# ATSAMG55G19 register map
Vendor: Microchip Technology; Series: SAMG55; File version: 0
CPU: CM4 r0p1, little endian, MPU, FPU, 4 interrupt priority bits, 50 interrupts
Registers are 32-bit, read-write, reset 0x0 unless marked. A register's access mark holds for its fields unless they carry their own. Offsets are from the block's base; [hi:lo] are bit positions.

## MEM2MEM — Memory to Memory
Base 0x40028000
0x00 THR — Memory to Memory Transfer Holding Register
  [31:0] THDATA — Transfer Holding Data
0x04 MR — Memory to Memory Mode Register
  [1:0] TSIZE — Transfer Size
    0=T_8BIT (The buffer size is defined in byte.); 1=T_16BIT (The buffer size is defined in half-word (16-bit).); 2=T_32BIT (The buffer size is defined in word (32-bit). Default value.)
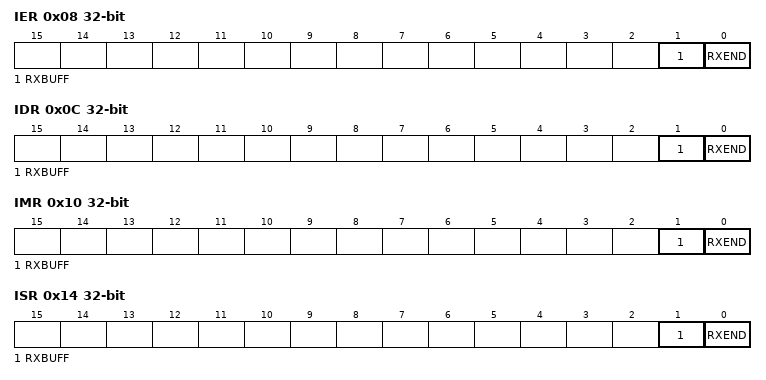
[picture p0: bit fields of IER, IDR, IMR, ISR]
0x08 IER wo — Memory to Memory Interrupt Enable Register
  [1] RXBUFF — Buffer Full Interrupt Enable
  [0] RXEND — End of Transfer Interrupt Enable
0x0C IDR wo — Memory to Memory Interrupt Disable Register
  [1] RXBUFF — Buffer Full Interrupt Disable
  [0] RXEND — End of Transfer Interrupt Disable
0x10 IMR ro — Memory to Memory Interrupt Mask Register
  [1] RXBUFF — Buffer Full Interrupt Mask
  [0] RXEND — End of Transfer Interrupt Mask
0x14 ISR ro — Memory to Memory Interrupt Status Register
  [1] RXBUFF — Buffer Full
  [0] RXEND — End of Transfer
0x100 RPR — Receive Pointer Register
  [31:0] RXPTR
0x104 RCR — Receive Counter Register
  [15:0] RXCTR
0x108 TPR — Transmit Pointer Register
  [31:0] TXPTR — Transmit Counter Register
0x10C TCR — Transmit Counter Register
  [15:0] TXCTR
0x110 RNPR — Receive Next Pointer Register
  [31:0] RXNPTR — Receive Next Pointer
0x114 RNCR — Receive Next Counter Register
  [15:0] RXNCTR — Receive Next Counter
0x118 TNPR — Transmit Next Pointer Register
  [31:0] TXNPTR — Transmit Next Pointer
0x11C TNCR — Transmit Next Counter Register
  [15:0] TXNCTR — Transmit Counter Next
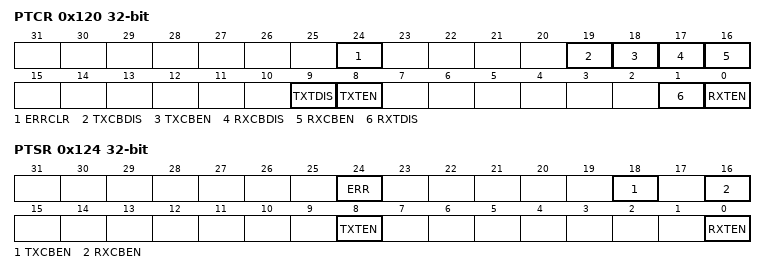
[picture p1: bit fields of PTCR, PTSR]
0x120 PTCR wo — Transfer Control Register
  [24] ERRCLR — Transfer Bus Error Clear
  [19] TXCBDIS — Transmitter Circular Buffer Disable
  [18] TXCBEN — Transmitter Circular Buffer Enable
  [17] RXCBDIS — Receiver Circular Buffer Disable
  [16] RXCBEN — Receiver Circular Buffer Enable
  [9] TXTDIS — Transmitter Transfer Disable
  [8] TXTEN — Transmitter Transfer Enable
  [1] RXTDIS — Receiver Transfer Disable
  [0] RXTEN — Receiver Transfer Enable
0x124 PTSR ro — Transfer Status Register
  [24] ERR — Transfer Bus Error
  [18] TXCBEN — Transmitter Circular Buffer Enable
  [16] RXCBEN — Receiver Circular Buffer Enable
  [8] TXTEN — Transmitter Transfer Enable
  [0] RXTEN — Receiver Transfer Enable

## PDMIC0 — Pulse Density Modulation Interface Controller
Base 0x4002C000; register names take the prefix PDMIC_
Same registers: PDMIC1 0x40030000
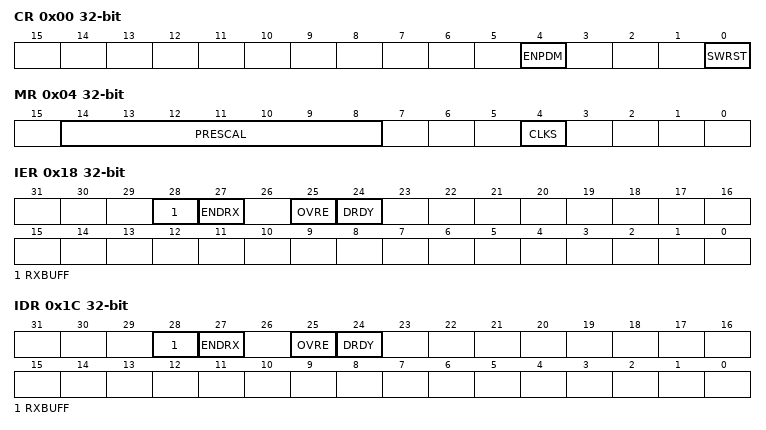
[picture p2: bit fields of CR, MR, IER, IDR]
0x00 CR — Control Register
  [4] ENPDM — Enable PDM
  [0] SWRST — Software Reset
0x04 MR — Mode Register
  [14:8] PRESCAL — Prescaler Rate Selection
  [4] CLKS — Clock Source Selection
0x14 CDR ro — Converted Data Register
  [31:0] DATA — Data Converted
0x18 IER wo — Interrupt Enable Register
  [28] RXBUFF — Receive Buffer Full Interrupt Enable
  [27] ENDRX — End of Receive Buffer Interrupt Enable
  [25] OVRE — Overrun Error Interrupt Enable
  [24] DRDY — Data Ready Interrupt Enable
0x1C IDR wo — Interrupt Disable Register
  [28] RXBUFF — Receive Buffer Full Interrupt Disable
  [27] ENDRX — End of Receive Buffer Interrupt Disable
  [25] OVRE — General Overrun Error Interrupt Disable
  [24] DRDY — Data Ready Interrupt Disable
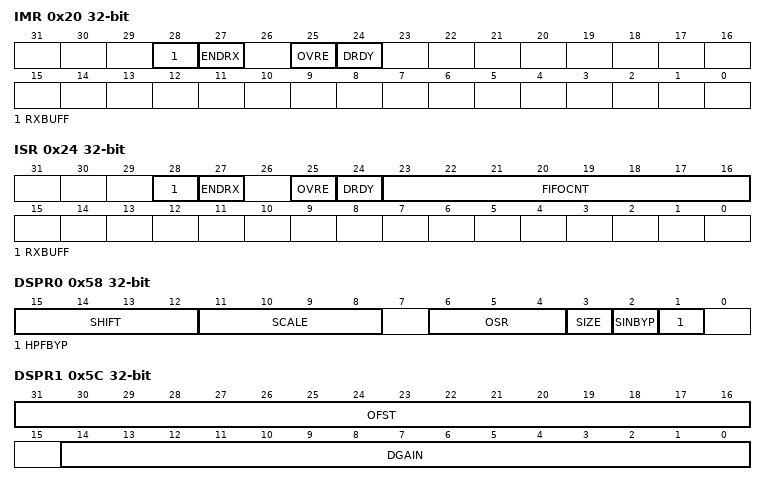
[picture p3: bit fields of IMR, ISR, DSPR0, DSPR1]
0x20 IMR ro — Interrupt Mask Register
  [28] RXBUFF — Receive Buffer Full Interrupt Mask
  [27] ENDRX — End of Receive Buffer Interrupt Mask
  [25] OVRE — General Overrun Error Interrupt Mask
  [24] DRDY — Data Ready Interrupt Mask
0x24 ISR ro — Interrupt Status Register
  [28] RXBUFF — RX Buffer Full
  [27] ENDRX — End of RX Buffer
  [25] OVRE — Overrun Error
  [24] DRDY — Data Ready
  [23:16] FIFOCNT — FIFO Count
0x58 DSPR0 — DSP Configuration Register 0
  [15:12] SHIFT — Data Shift
  [11:8] SCALE — Data Scale
  [6:4] OSR — Oversampling Ratio
    0=Oversampling ratio is 128; 1=Oversampling ratio is 64
  [3] SIZE — Data Size
  [2] SINBYP — SINCC Filter Bypass
  [1] HPFBYP — High-Pass Filter Bypass
0x5C DSPR1 — DSP Configuration Register 1
  [31:16] OFST — Offset Correction
  [14:0] DGAIN — Gain Correction
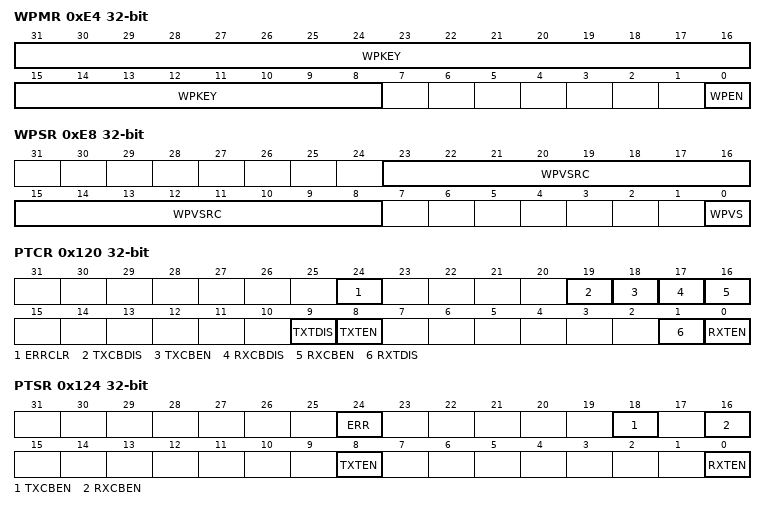
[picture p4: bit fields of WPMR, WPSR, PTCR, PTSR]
0xE4 WPMR — Write Protection Mode Register
  [31:8] WPKEY — Write Protect Key
    0x414443=PASSWD (Writing any other value in this field aborts the write operation of the WPEN bit.Always reads as 0.)
  [0] WPEN — Write Protection Enable
0xE8 WPSR ro — Write Protection Status Register
  [23:8] WPVSRC — Write Protection Violation Source
  [0] WPVS — Write Protection Violation Status
0x100 RPR — Receive Pointer Register
  [31:0] RXPTR
0x104 RCR — Receive Counter Register
  [15:0] RXCTR
0x110 RNPR — Receive Next Pointer Register
  [31:0] RXNPTR — Receive Next Pointer
0x114 RNCR — Receive Next Counter Register
  [15:0] RXNCTR — Receive Next Counter
0x120 PTCR wo — Transfer Control Register
  [24] ERRCLR — Transfer Bus Error Clear
  [19] TXCBDIS — Transmitter Circular Buffer Disable
  [18] TXCBEN — Transmitter Circular Buffer Enable
  [17] RXCBDIS — Receiver Circular Buffer Disable
  [16] RXCBEN — Receiver Circular Buffer Enable
  [9] TXTDIS — Transmitter Transfer Disable
  [8] TXTEN — Transmitter Transfer Enable
  [1] RXTDIS — Receiver Transfer Disable
  [0] RXTEN — Receiver Transfer Enable
0x124 PTSR ro — Transfer Status Register
  [24] ERR — Transfer Bus Error
  [18] TXCBEN — Transmitter Circular Buffer Enable
  [16] RXCBEN — Receiver Circular Buffer Enable
  [8] TXTEN — Transmitter Transfer Enable
  [0] RXTEN — Receiver Transfer Enable

## Notices in the file
Copyright (c) 2026 Microchip Technology Inc.
SPDX-License-Identifier: Apache-2.0
Licensed under the Apache License, Version 2.0 (the "License");
you may not use this file except in compliance with the License.
You may obtain a copy of the License at
http://www.apache.org/licenses/LICENSE-2.0
Unless required by applicable law or agreed to in writing, software
distributed under the License is distributed on an "AS IS" BASIS,
WITHOUT WARRANTIES OR CONDITIONS OF ANY KIND, either express or implied.
See the License for the specific language governing permissions and
limitations under the License.
